VERSION ""

NS_ :

BS_:

BU_: SMU_FR SMU_FL FCU GPS_F IMU_F BSPD TKU PTU Kistler_GSS SW
VAL_TABLE_ BSPD_EMERGENCY_VT 1 "BSPD OK" 0 "Emergency Open" ;
VAL_TABLE_ Kistler_control_VT 241 "Swtich on LED" 240 "Switch off LED" 171 "Reset trip meter" 170 "Reset sensor" 2 "Sensor leafs self test" 1 "Sensor goes into self test" 0 "Send data and ID" ;

BO_ 1955 SW_Alive: 1 SW
 SG_ SW_Alive : 0|8@1+ (1,0) [0|255] "" Vector__XXX

BO_ 1972 BSPD_State: 1 BSPD
 SG_ BSPD_Alive : 0|8@1+ (1,0) [0|255] "" Vector__XXX

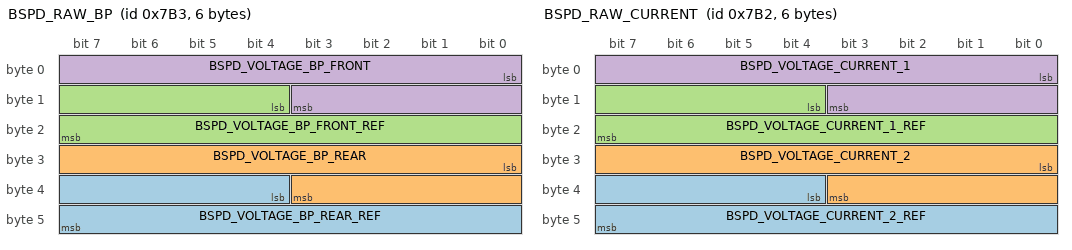
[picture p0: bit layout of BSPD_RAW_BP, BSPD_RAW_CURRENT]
BO_ 1971 BSPD_RAW_BP: 6 BSPD
 SG_ BSPD_VOLTAGE_BP_REAR_REF : 36|12@1+ (0.0015004,0) [0|6.144138] "V" Vector__XXX
 SG_ BSPD_VOLTAGE_BP_REAR : 24|12@1+ (0.0015004,0) [0|6.144138] "V" Vector__XXX
 SG_ BSPD_VOLTAGE_BP_FRONT_REF : 12|12@1+ (0.0015004,0) [0|6.144138] "V" Vector__XXX
 SG_ BSPD_VOLTAGE_BP_FRONT : 0|12@1+ (0.0015004,0) [0|6.144138] "V" Vector__XXX

BO_ 1970 BSPD_RAW_CURRENT: 6 BSPD
 SG_ BSPD_VOLTAGE_CURRENT_2_REF : 36|12@1+ (0.0015004,0) [0|6.144138] "V" Vector__XXX
 SG_ BSPD_VOLTAGE_CURRENT_2 : 24|12@1+ (0.0015004,0) [0|6.144138] "V" Vector__XXX
 SG_ BSPD_VOLTAGE_CURRENT_1_REF : 12|12@1+ (0.0015004,0) [0|6.144138] "V" Vector__XXX
 SG_ BSPD_VOLTAGE_CURRENT_1 : 0|12@1+ (0.0015004,0) [0|6.144138] "V" Vector__XXX

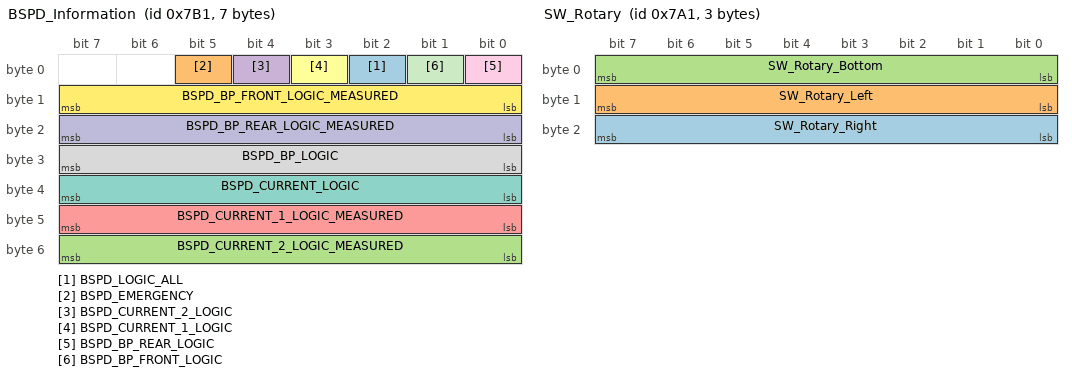
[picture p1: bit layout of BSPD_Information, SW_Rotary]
BO_ 1969 BSPD_Information: 7 BSPD
 SG_ BSPD_LOGIC_ALL : 2|1@1+ (1,0) [0|1] "" Vector__XXX
 SG_ BSPD_EMERGENCY : 5|1@1+ (1,0) [0|1] "" Vector__XXX
 SG_ BSPD_CURRENT_2_LOGIC_MEASURED : 48|8@1+ (1,0) [0|255] "" Vector__XXX
 SG_ BSPD_CURRENT_2_LOGIC : 4|1@1+ (1,0) [0|1] "" Vector__XXX
 SG_ BSPD_CURRENT_1_LOGIC_MEASURED : 40|8@1+ (1,0) [0|255] "" Vector__XXX
 SG_ BSPD_CURRENT_1_LOGIC : 3|1@1+ (1,0) [0|1] "" Vector__XXX
 SG_ BSPD_CURRENT_LOGIC : 32|8@1+ (1,0) [0|255] "" Vector__XXX
 SG_ BSPD_BP_LOGIC : 24|8@1+ (1,0) [0|255] "" Vector__XXX
 SG_ BSPD_BP_REAR_LOGIC : 0|1@1+ (1,0) [0|1] "" Vector__XXX
 SG_ BSPD_BP_REAR_LOGIC_MEASURED : 16|8@1+ (1,0) [0|255] "" Vector__XXX
 SG_ BSPD_BP_FRONT_LOGIC : 1|1@1+ (1,0) [0|1] "" Vector__XXX
 SG_ BSPD_BP_FRONT_LOGIC_MEASURED : 8|8@1+ (1,0) [0|255] "" Vector__XXX

BO_ 1968 BSPD_ErrClkInfo: 3 BSPD
 SG_ BSPD_TimeToReset : 0|12@1+ (0.00390625,0) [0|12] "s" Vector__XXX
 SG_ BSPD_ShutOffTime : 16|8@1+ (3.90625,0) [0|60] "ms" Vector__XXX

BO_ 1954 SW_Encoder: 4 SW
 SG_ FCU_ADC_2 : 16|16@1+ (1,0) [0|65535] "" Vector__XXX
 SG_ FCU_ADC_1 : 0|16@1+ (1,0) [0|65535] "" Vector__XXX

BO_ 1953 SW_Rotary: 3 SW
 SG_ SW_Rotary_Right : 16|8@1- (1,0) [0|12] "" Vector__XXX
 SG_ SW_Rotary_Left : 8|8@1- (1,0) [0|12] "" Vector__XXX
 SG_ SW_Rotary_Bottom : 0|8@1- (1,0) [0|12] "" Vector__XXX

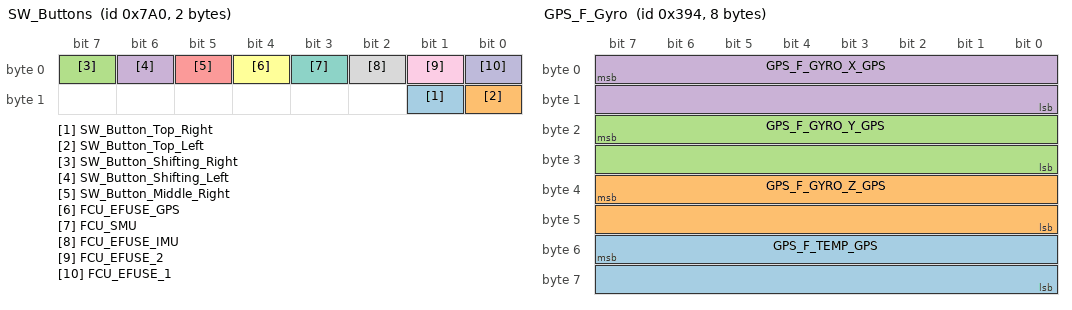
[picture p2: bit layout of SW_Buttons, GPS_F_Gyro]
BO_ 1952 SW_Buttons: 2 SW
 SG_ SW_Button_Top_Right : 9|1@1+ (1,0) [0|1] "" Vector__XXX
 SG_ SW_Button_Top_Left : 8|1@1+ (1,0) [0|1] "" Vector__XXX
 SG_ SW_Button_Shifting_Right : 7|1@1+ (1,0) [0|1] "" Vector__XXX
 SG_ SW_Button_Shifting_Left : 6|1@1+ (1,0) [0|1] "" Vector__XXX
 SG_ SW_Button_Middle_Right : 5|1@1+ (1,0) [0|1] "" Vector__XXX
 SG_ FCU_EFUSE_GPS : 4|1@1+ (1,0) [0|1] "" Vector__XXX
 SG_ FCU_SMU : 3|1@1+ (1,0) [0|1] "" Vector__XXX
 SG_ FCU_EFUSE_IMU : 2|1@1+ (1,0) [0|1] "" Vector__XXX
 SG_ FCU_EFUSE_2 : 1|1@1+ (1,0) [0|1] "" Vector__XXX
 SG_ FCU_EFUSE_1 : 0|1@1+ (1,0) [0|1] "" Vector__XXX

BO_ 1140 GPS_F_Pos: 8 GPS_F
 SG_ GPS_F_Lon_dez : 39|32@0+ (1E-007,0) [0|0] "deg" Vector__XXX
 SG_ GPS_F_Lat_dez : 7|32@0+ (1E-007,0) [0|0] "deg" Vector__XXX

BO_ 916 GPS_F_Gyro: 8 GPS_F
 SG_ GPS_F_TEMP_GPS : 55|16@0- (0.1,0) [0|0] "°C" Vector__XXX
 SG_ GPS_F_GYRO_Z_GPS : 39|16@0+ (0.08,-2621.36) [0|0] "deg/s" Vector__XXX
 SG_ GPS_F_GYRO_Y_GPS : 23|16@0+ (0.08,-2621.36) [0|0] "deg/s" Vector__XXX
 SG_ GPS_F_GYRO_X_GPS : 7|16@0+ (0.08,-2621.36) [0|0] "deg/s" Vector__XXX

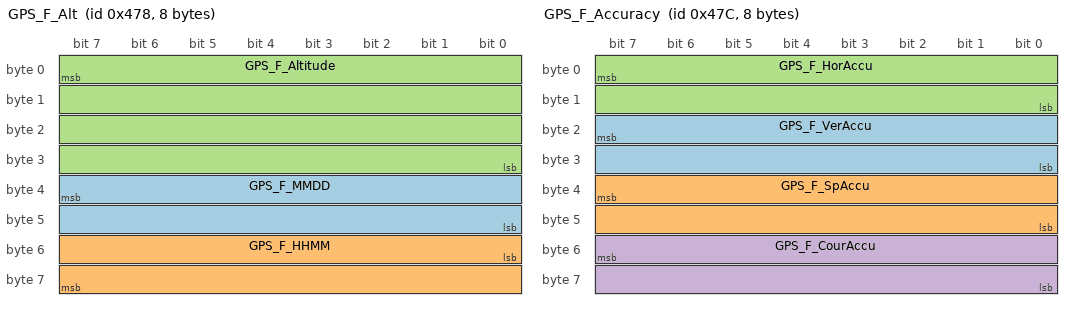
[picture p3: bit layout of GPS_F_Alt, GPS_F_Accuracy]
BO_ 1144 GPS_F_Alt: 8 GPS_F
 SG_ GPS_F_MMDD : 39|16@0+ (0.01,0) [0|0] "" Vector__XXX
 SG_ GPS_F_HHMM : 48|16@1+ (0.01,0) [0|0] "" Vector__XXX
 SG_ GPS_F_Altitude : 7|32@0+ (0.01,0) [0|0] "m" Vector__XXX

BO_ 1148 GPS_F_Accuracy: 8 GPS_F
 SG_ GPS_F_VerAccu : 23|16@0+ (0.001,0) [0|0] "m" Vector__XXX
 SG_ GPS_F_SpAccu : 39|16@0+ (0.036,0) [0|0] "km/h" Vector__XXX
 SG_ GPS_F_HorAccu : 7|16@0+ (0.001,0) [0|0] "m" Vector__XXX
 SG_ GPS_F_CourAccu : 55|16@0+ (0.01,0) [0|0] "deg" Vector__XXX

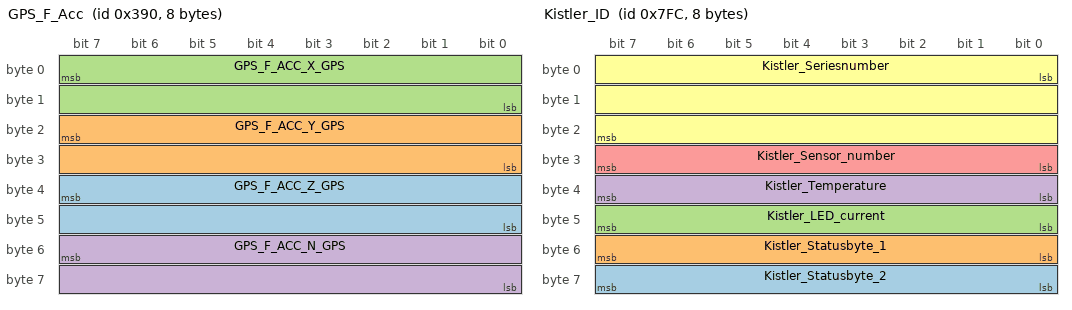
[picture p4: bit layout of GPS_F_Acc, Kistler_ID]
BO_ 912 GPS_F_Acc: 8 GPS_F
 SG_ GPS_F_ACC_Z_GPS : 39|16@0+ (0.0025,-81.9175) [0|0] "m/s" Vector__XXX
 SG_ GPS_F_ACC_Y_GPS : 23|16@0+ (0.0025,-81.9175) [0|0] "m/s" Vector__XXX
 SG_ GPS_F_ACC_X_GPS : 7|16@0+ (0.0025,-81.9175) [0|0] "m/s" Vector__XXX
 SG_ GPS_F_ACC_N_GPS : 55|16@0+ (0.0025,0) [0|0] "m/s" Vector__XXX

BO_ 2044 Kistler_ID: 8 Kistler_GSS
 SG_ Kistler_Statusbyte_2 : 56|8@1+ (1,0) [0|255] "" Vector__XXX
 SG_ Kistler_Statusbyte_1 : 48|8@1+ (1,0) [0|0] "" Vector__XXX
 SG_ Kistler_LED_current : 40|8@1+ (0.01,0) [0|2.55] "A" Vector__XXX
 SG_ Kistler_Temperature : 32|8@1- (1,0) [-128|127] "°C" Vector__XXX
 SG_ Kistler_Sensor_number : 24|8@1+ (1,0) [0|0] "" Vector__XXX
 SG_ Kistler_Seriesnumber : 0|24@1+ (1,0) [0|16777215] "" Vector__XXX

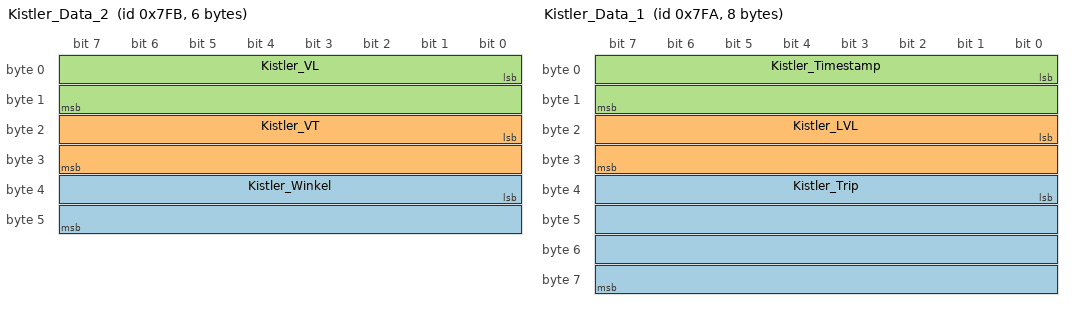
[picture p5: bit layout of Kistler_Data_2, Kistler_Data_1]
BO_ 2043 Kistler_Data_2: 6 Kistler_GSS
 SG_ Kistler_Winkel : 32|16@1+ (0.01,0) [0|655.35] "°" Vector__XXX
 SG_ Kistler_VT : 16|16@1- (0.01,0) [-327.68|327.67] "m/s" Vector__XXX
 SG_ Kistler_VL : 0|16@1+ (0.01,0) [0|655.35] "m/s" Vector__XXX

BO_ 2042 Kistler_Data_1: 8 Kistler_GSS
 SG_ Kistler_Trip : 32|32@1+ (0.001,0) [0|4294967.295] "m" Vector__XXX
 SG_ Kistler_LVL : 16|16@1+ (0.01,0) [0|655.35] "m/s" Vector__XXX
 SG_ Kistler_Timestamp : 0|16@1+ (4,0) [0|262140] "ms" Vector__XXX

BO_ 1792 Kistler_Control: 2 Kistler_GSS
 SG_ Kistler_Control : 0|2@1+ (1,0) [0|0] "" Vector__XXX

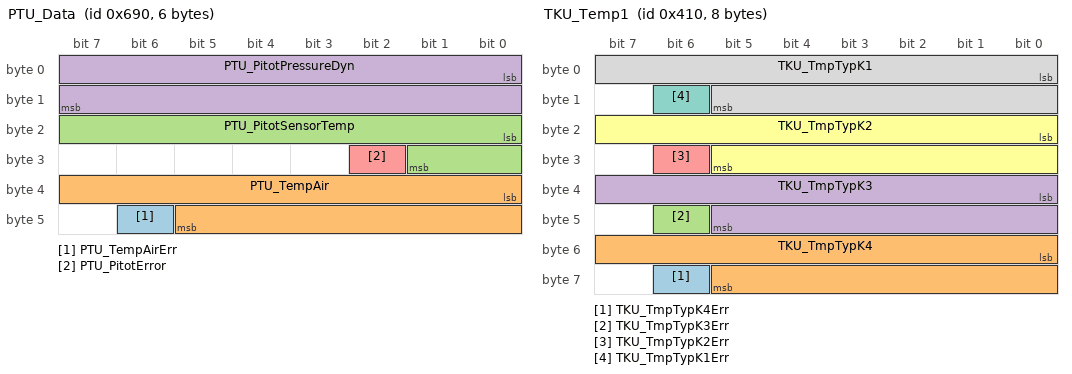
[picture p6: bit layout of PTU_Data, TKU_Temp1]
BO_ 1680 PTU_Data: 6 PTU
 SG_ PTU_TempAirErr : 46|1@1+ (1,0) [0|1] "" Vector__XXX
 SG_ PTU_TempAir : 32|14@1- (0.25,0) [-250|1600] "°C" Vector__XXX
 SG_ PTU_PitotSensorTemp : 16|10@1+ (0.1956,-50) [-50|100] "°C" Vector__XXX
 SG_ PTU_PitotPressureDyn : 0|16@1- (0.2105,0) [-6895|6895] "Pa" Vector__XXX
 SG_ PTU_PitotError : 26|1@1+ (1,0) [0|1] "" Vector__XXX

BO_ 1857 PTU_State: 2 PTU
 SG_ PTU_Error : 8|8@1+ (1,0) [0|255] "" Vector__XXX
 SG_ PTU_Alive : 0|8@1+ (1,0) [0|255] "" Vector__XXX

BO_ 1044 TKU_Temp2: 8 TKU
 SG_ TKU_TmpTypT5Err : 14|1@1+ (1,0) [0|1] "" Vector__XXX
 SG_ TKU_TmpTypT5 : 0|14@1- (0.25,0) [-250|400] "°C" Vector__XXX

BO_ 1040 TKU_Temp1: 8 TKU
 SG_ TKU_TmpTypK4Err : 62|1@1+ (1,0) [0|1] "" Vector__XXX
 SG_ TKU_TmpTypK4 : 48|14@1- (0.25,0) [-250|1600] "°C" Vector__XXX
 SG_ TKU_TmpTypK3Err : 46|1@1+ (1,0) [0|1] "" Vector__XXX
 SG_ TKU_TmpTypK3 : 32|14@1- (0.25,0) [-250|1600] "°C" Vector__XXX
 SG_ TKU_TmpTypK2Err : 30|1@1+ (1,0) [0|1] "" Vector__XXX
 SG_ TKU_TmpTypK2 : 16|14@1- (0.25,0) [-250|1600] "°C" Vector__XXX
 SG_ TKU_TmpTypK1Err : 14|1@1+ (1,0) [0|1] "" Vector__XXX
 SG_ TKU_TmpTypK1 : 0|14@1- (0.25,0) [-250|1600] "°C" Vector__XXX

BO_ 1536 TKU_State: 3 TKU
 SG_ TKU_Error : 8|8@1+ (1,0) [0|0] "" Vector__XXX
 SG_ TKU_Alive : 0|8@1+ (1,0) [0|255] "" Vector__XXX

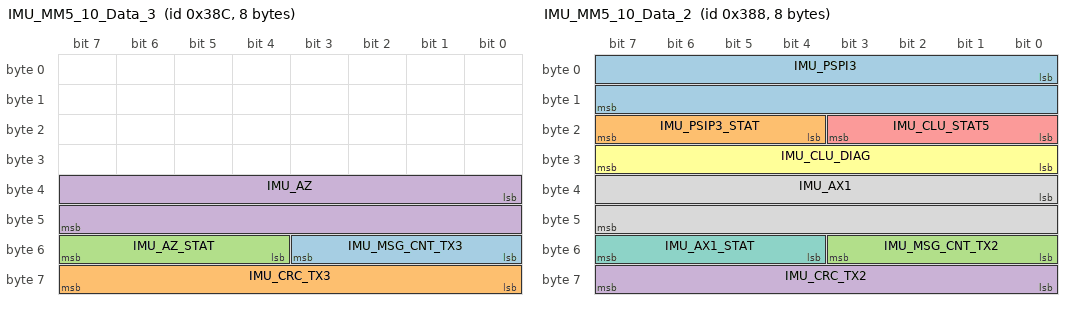
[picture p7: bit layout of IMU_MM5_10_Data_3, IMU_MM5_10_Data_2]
BO_ 908 IMU_MM5_10_Data_3: 8 IMU_F
 SG_ IMU_MSG_CNT_TX3 : 48|4@1+ (1,0) [0|15] "" Vector__XXX
 SG_ IMU_CRC_TX3 : 56|8@1+ (1,0) [0|255] "" Vector__XXX
 SG_ IMU_AZ_STAT : 52|4@1+ (1,0) [0|15] "" Vector__XXX
 SG_ IMU_AZ : 32|16@1+ (0.000127465,-4.1768) [-4.1768|4.1765] "g" Vector__XXX

BO_ 904 IMU_MM5_10_Data_2: 8 IMU_F
 SG_ IMU_PSPI3 : 0|16@1+ (0.005,-163.84) [-163.84|163.835] "°/s" Vector__XXX
 SG_ IMU_PSIP3_STAT : 20|4@1+ (1,0) [0|15] "" Vector__XXX
 SG_ IMU_MSG_CNT_TX2 : 48|4@1+ (1,0) [0|15] "" Vector__XXX
 SG_ IMU_CRC_TX2 : 56|8@1+ (1,0) [0|255] "" Vector__XXX
 SG_ IMU_CLU_STAT5 : 16|4@1+ (1,0) [0|15] "" Vector__XXX
 SG_ IMU_CLU_DIAG : 24|8@1+ (1,0) [0|255] "" Vector__XXX
 SG_ IMU_AX1_STAT : 52|4@1+ (1,0) [0|0] "" Vector__XXX
 SG_ IMU_AX1 : 32|16@1+ (0.000127465,-4.1768) [-4.1768|4.1765] "g" Vector__XXX

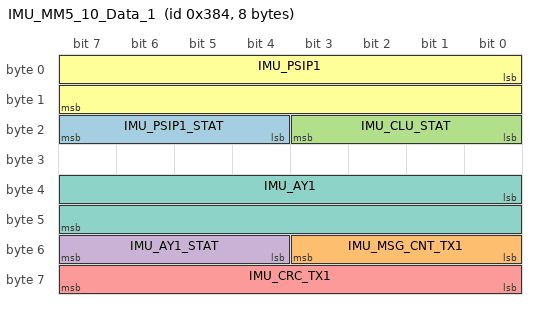
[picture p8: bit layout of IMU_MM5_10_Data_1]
BO_ 900 IMU_MM5_10_Data_1: 8 IMU_F
 SG_ IMU_PSIP1_STAT : 20|4@1+ (1,0) [0|15] "" Vector__XXX
 SG_ IMU_MSG_CNT_TX1 : 48|4@1+ (1,0) [0|15] "" Vector__XXX
 SG_ IMU_CLU_STAT : 16|4@1+ (1,0) [0|15] "" Vector__XXX
 SG_ IMU_AY1_STAT : 52|4@1+ (1,0) [0|15] "" Vector__XXX
 SG_ IMU_CRC_TX1 : 56|8@1+ (1,0) [0|255] "" Vector__XXX
 SG_ IMU_PSIP1 : 0|16@1+ (0.005,-163.84) [-163.84|163.83] "°/s" Vector__XXX
 SG_ IMU_AY1 : 32|16@1+ (0.000127465,-4.1768) [-4.1768|4.1765] "g" Vector__XXX

CM_ SG_ 1144 GPS_F_MMDD "Month:Day";
CM_ SG_ 1144 GPS_F_HHMM "Hour:Minute";
BA_DEF_ SG_  "GenSigStartValue" FLOAT 0 100000000000;
BA_DEF_ SG_  "GenSigSendType" ENUM  "Cyclic","OnWrite","OnWriteWithRepetition","OnChange","OnChangeWithRepetition","IfActive","IfActiveWithRepetition","NoSigSendType","NotUsed","NotUsed","NotUsed","NotUsed","NotUsed";
BA_DEF_ BO_  "GenMsgILSupport" ENUM  "No","Yes";
BA_DEF_ BO_  "GenMsgSendType2" ENUM  "Zyklisch","Ereignisgesteuert","dummy","Auf Anfrage";
BA_DEF_ BO_  "GenMsgFastOnStart" INT 10 500;
BA_DEF_ BO_  "GenMsgCycleTimeActive" INT 1 100;
BA_DEF_ BO_  "VFrameFormat" ENUM  "StandardCAN","ExtendedCAN","reserved","reserved","reserved","reserved","reserved","reserved","reserved","reserved","reserved","reserved","reserved","reserved","StandardCAN_FD","ExtendedCAN_FD";
BA_DEF_ BO_  "GenMsgSendType" ENUM  "Cyclic","NotUsed","NotUsed","NotUsed","NotUsed","NotUsed","NotUsed","IfActive","NoMsgSendType","NotUsed","vector_leerstring";
BA_DEF_  "BusType" STRING ;
BA_DEF_DEF_  "GenSigStartValue" 0;
BA_DEF_DEF_  "GenSigSendType" "Cyclic";
BA_DEF_DEF_  "GenMsgILSupport" "Yes";
BA_DEF_DEF_  "GenMsgSendType2" "Zyklisch";
BA_DEF_DEF_  "GenMsgFastOnStart" 10;
BA_DEF_DEF_  "GenMsgCycleTimeActive" 10;
BA_DEF_DEF_  "VFrameFormat" "ExtendedCAN_FD";
BA_DEF_DEF_  "GenMsgSendType" "NoMsgSendType";
BA_DEF_DEF_  "BusType" "CAN";
BA_ "VFrameFormat" BO_ 1955 0;
BA_ "VFrameFormat" BO_ 1972 0;
BA_ "VFrameFormat" BO_ 1971 0;
BA_ "VFrameFormat" BO_ 1970 0;
BA_ "VFrameFormat" BO_ 1969 0;
BA_ "VFrameFormat" BO_ 1968 0;
BA_ "VFrameFormat" BO_ 1954 0;
BA_ "VFrameFormat" BO_ 1953 0;
BA_ "VFrameFormat" BO_ 1952 0;
BA_ "VFrameFormat" BO_ 1140 0;
BA_ "VFrameFormat" BO_ 916 0;
BA_ "VFrameFormat" BO_ 1144 0;
BA_ "VFrameFormat" BO_ 1148 0;
BA_ "VFrameFormat" BO_ 912 0;
BA_ "VFrameFormat" BO_ 2044 0;
BA_ "VFrameFormat" BO_ 2043 0;
BA_ "VFrameFormat" BO_ 2042 0;
BA_ "VFrameFormat" BO_ 1792 0;
BA_ "VFrameFormat" BO_ 1680 0;
BA_ "VFrameFormat" BO_ 1857 0;
BA_ "VFrameFormat" BO_ 1044 0;
BA_ "VFrameFormat" BO_ 1040 0;
BA_ "VFrameFormat" BO_ 1536 0;
BA_ "VFrameFormat" BO_ 908 0;
BA_ "VFrameFormat" BO_ 904 0;
BA_ "VFrameFormat" BO_ 900 0;
BA_ "GenSigStartValue" SG_ 1968 BSPD_ShutOffTime 0.256;
VAL_ 1969 BSPD_EMERGENCY 1 "BSPD OK" 0 "Emergency Open" ;
VAL_ 1792 Kistler_Control 241 "Swtich on LED" 240 "Switch off LED" 171 "Reset trip meter" 170 "Reset sensor" 2 "Sensor leafs self test" 1 "Sensor goes into self test" 0 "Send data and ID" ;
